# iND83213A register map
Vendor: Indiemicro; Series: Rugby; File version: 1.0
CPU: CM0 r0p1, selectable endian, no MPU, no FPU, 4 interrupt priority bits
Registers are 32-bit, read-write, no defined reset value unless marked. A register's access mark holds for its fields unless they carry their own. Offsets are from the block's base; [hi:lo] are bit positions; {n}, {i} and the like mark numbered series.

## PWM_AUX — Control (and status) registers for the pulse width modulation waveform generator.
Base 0x50010900; register names take the prefix PWM_AUX_
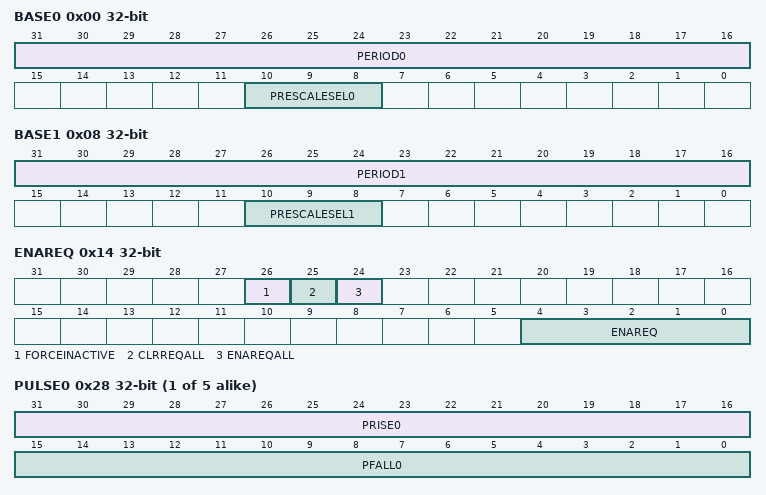
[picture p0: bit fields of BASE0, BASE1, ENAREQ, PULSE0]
0x00 BASE0 — Base 0 functions
  [31:16] PERIOD0 — Period. Specifies the period of the output waveform in terms of a number of prescaler output cycles.
  [10:8] PRESCALESEL0 — Prescaler select. Defines the ratio between the system clock and the clock used for the waveform generator. 0x0: Divide by 1 0x1: Divide by 2 0x2: Divide by 4 0x3: Divide by 8 0x4: Divide by 16 0x5: Divide by 64 0x6: Divide by 256 0x7: Divide by 1024
0x04 PWMCNT0 — PWM Count Value
  [15:0] PWMCNT0 ro — PWM counter value to give a sense about the current period
0x08 BASE1 — Base 1 functions
  [31:16] PERIOD1 — Period. Specifies the period of the output waveform in terms of a number of prescaler output cycles.
  [10:8] PRESCALESEL1 — Prescaler select. Defines the ratio between the system clock and the clock used for the waveform generator. 0x0: Divide by 1 0x1: Divide by 2 0x2: Divide by 4 0x3: Divide by 8 0x4: Divide by 16 0x5: Divide by 64 0x6: Divide by 256 0x7: Divide by 1024
0x0C PWMCNT1 — PWM Count Value
  [15:0] PWMCNT1 ro — PWM counter value to give a sense about the current period
0x10 BASESEL — Base Timer Select for individual Channels
  [4:0] BASE_SEL — Base Timer Selects:1=Select BASE1, 0=Select BASE0.
0x14 ENAREQ — Enable request
  [26] FORCEINACTIVE — Set to force PWM signals return to initial value immediately.
  [25] CLRREQALL wo — Write 1 to clear all ENA_REQ bits; Write 0 has no effects.
  [24] ENAREQALL wo — Write 1 to enable all ENA_REQ bits; Write 0 has no effects.
  [4:0] ENAREQ — Set to enable the waveform generator.
0x18 ENASTS — Enable status
  [4:0] ENASTS ro — Status of enable in the waveform generator.
0x1C INIT — Intial State of Outputs
  [4:0] INIT — Set to initialise the output waveform.
0x20 INV — Invert
  [4:0] INVERT — Set to invert the output waveform.
0x24 UPDATE
  [1:0] UPDATE — Set to trigger consumption of new PULSE parameters (invert,prescale_sel,period,pulse start & stop). The flag is automatically cleared by the hardware when the settings are consumed, so reading a high value indicates that an update is still pending.
{0x28+4i} PULSE{i} (i=0..4) — PWM{i} pulse setup
  [31:16] PRISE{i} — Pulse Rise. Specifies the pulse rise of the output waveform in terms of a number of prescaler output cycles. However, if INVERT is set it determines the pulse fall timing.
  [15:0] PFALL{i} — Pulse Fall. Specifies the pulse fall of the output waveform in terms of a number of prescaler output cycles. However, if INVERT is set it determines the pulse rise timing.
0x3C INTPOSEDGENA — PWM posedge interrupt enable
  [4:0] INTPOSEDGENA — Interrupt enable. bit[4:0]: posedge interrupt enable.
0x40 INTNEGEDGENA — PWM negedge interrupt enable
  [4:0] INTNEGEDGENA — Interrupt enable. bit[4:0]: negedge interrupt enable.
0x44 INTPOSEDGCLR — PWM posedge interrupt control
  [4:0] INTPOSEDGCLR wo — Interrupt clear. bit[4:0] : posedge interrupt clear.
0x48 INTNEGEDGCLR — PWM negedge interrupt control
  [4:0] INTNEGEDGCLR wo — Interrupt clear. bit[4:0] : negedge interrupt clear.
0x4C INTPOSEDGSTS — PWM posedge interrupt status
  [4:0] INTPOSEDGSTS ro — Interrupt status. bit[4:0] : posedge interrupt status.
0x50 INTNEGEDGSTS — PWM negedge interrupt status
  [4:0] INTNEGEDGSTS ro — Interrupt status. bit[4:0] : negedge interrupt status.
0x54 INTPOSEDGIRQ — PWM posedge interrupt active
  [4:0] INTPOSEDGIRQ ro — Interrupt active. bit[4:0] : posedge interrupt active.
0x58 INTNEGEDGIRQ — PWM negedge interrupt active
  [4:0] INTNEGEDGIRQ ro — Interrupt active. bit[4:0] : negedge interrupt active.
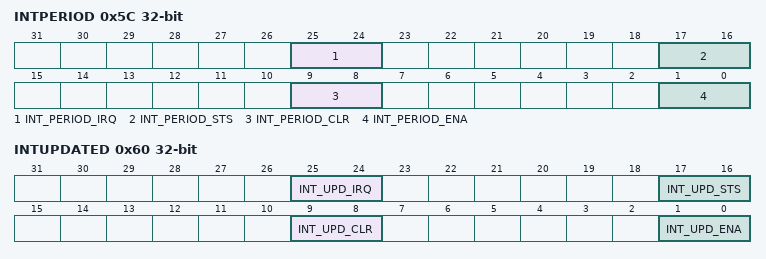
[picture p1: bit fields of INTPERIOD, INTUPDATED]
0x5C INTPERIOD — PWM Period interrupt control
  [25:24] INT_PERIOD_IRQ ro — Period Interrupt active.
  [17:16] INT_PERIOD_STS ro — Period Interrupt status.
  [9:8] INT_PERIOD_CLR wo — Period Interrupt clear.
  [1:0] INT_PERIOD_ENA — Period Interrupt enable.
0x60 INTUPDATED — PWM Updated interrupt control
  [25:24] INT_UPD_IRQ ro — Updated Interrupt active.
  [17:16] INT_UPD_STS ro — Updated Interrupt status.
  [9:8] INT_UPD_CLR wo — Updated Interrupt clear.
  [1:0] INT_UPD_ENA — Updated Interrupt enable.
